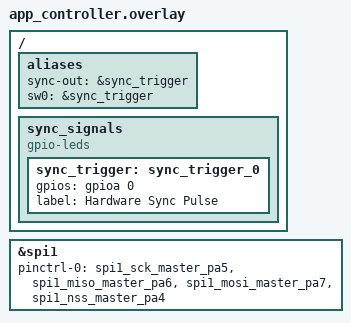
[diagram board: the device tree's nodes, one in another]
&spi1 {
	status = "okay";
	pinctrl-0 = <&spi1_sck_master_pa5 &spi1_miso_master_pa6 &spi1_mosi_master_pa7 &spi1_nss_master_pa4>;
	pinctrl-names = "default";
};

/ {
	aliases {
		sync-out = &sync_trigger;
		sw0 = &sync_trigger;
	};

	/* Use a dedicated node for the sync signal */
	sync_signals {
		compatible = "gpio-leds";
		sync_trigger: sync_trigger_0 {
			/* Adjust PA0 to your preferred physical pin */
			gpios = <&gpioa 0 GPIO_ACTIVE_HIGH>;
			label = "Hardware Sync Pulse";
		};
	};
};
